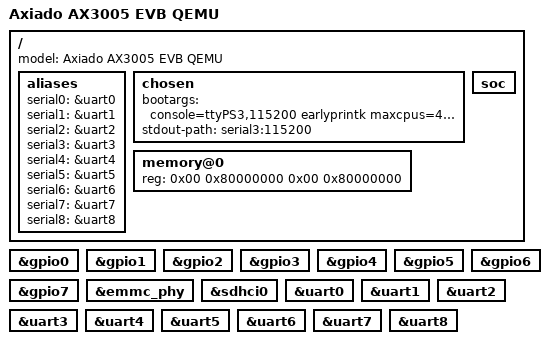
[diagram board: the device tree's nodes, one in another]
// SPDX-License-Identifier: GPL-2.0+
/*
 * DTS file for QEMU model of Axiado AX3005 SoC Evaluation board
 */

/dts-v1/;

#include "ax3005.dtsi"

/ {
	model = "Axiado AX3005 EVB QEMU";
	#address-cells = <2>;
	#size-cells = <2>;

	aliases {
		serial0 = &uart0;
		serial1 = &uart1;
		serial2 = &uart2;
		serial3 = &uart3;
		serial4 = &uart4;
		serial5 = &uart5;
		serial6 = &uart6;
		serial7 = &uart7;
		serial8 = &uart8;
	};

	chosen {
		bootargs = "console=ttyPS3,115200 earlyprintk maxcpus=4 nr_cpus=4 earlycon";
		stdout-path = "serial3:115200";
	};

	memory@0 {
		device_type = "memory";
		reg = <0x00 0x80000000 0x00 0x80000000>;
	};

	/delete-node/ display-subsystem;

	soc {
		/delete-node/ mailbox0;
		/delete-node/ mctp-mailbox;
		/delete-node/ pcie_x1;
		/delete-node/ hcp;
		/delete-node/ video;
	};
};

/delete-node/ &pci_ep_disp;
/delete-node/ &pci_ep_ctrl;
/delete-node/ &shm_ap_to_rot;
/delete-node/ &shm_rot_to_ap;
/delete-node/ &rot_fwu;
/delete-node/ &disp_ctrl;
/delete-node/ &hdmi;

&gpio0 {
	status = "okay";
};

&gpio1 {
	status = "okay";
};

&gpio2 {
	status = "okay";
};

&gpio3 {
	status = "okay";
};

&gpio4 {
	status = "okay";
};

&gpio5 {
	status = "okay";
};

&gpio6 {
	status = "okay";
};

&gpio7 {
	status = "okay";
};

&emmc_phy {
	status = "okay";
};

&sdhci0 {
	status = "okay";
};

&uart0 {
	status = "okay";
};

&uart1 {
	status = "okay";
};

&uart2 {
	status = "okay";
};

&uart3 {
	status = "okay";
};

&uart4 {
	status = "okay";
};

&uart5 {
	status = "okay";
};

&uart6 {
	status = "okay";
};

&uart7 {
	status = "okay";
};

&uart8 {
	status = "okay";
};
